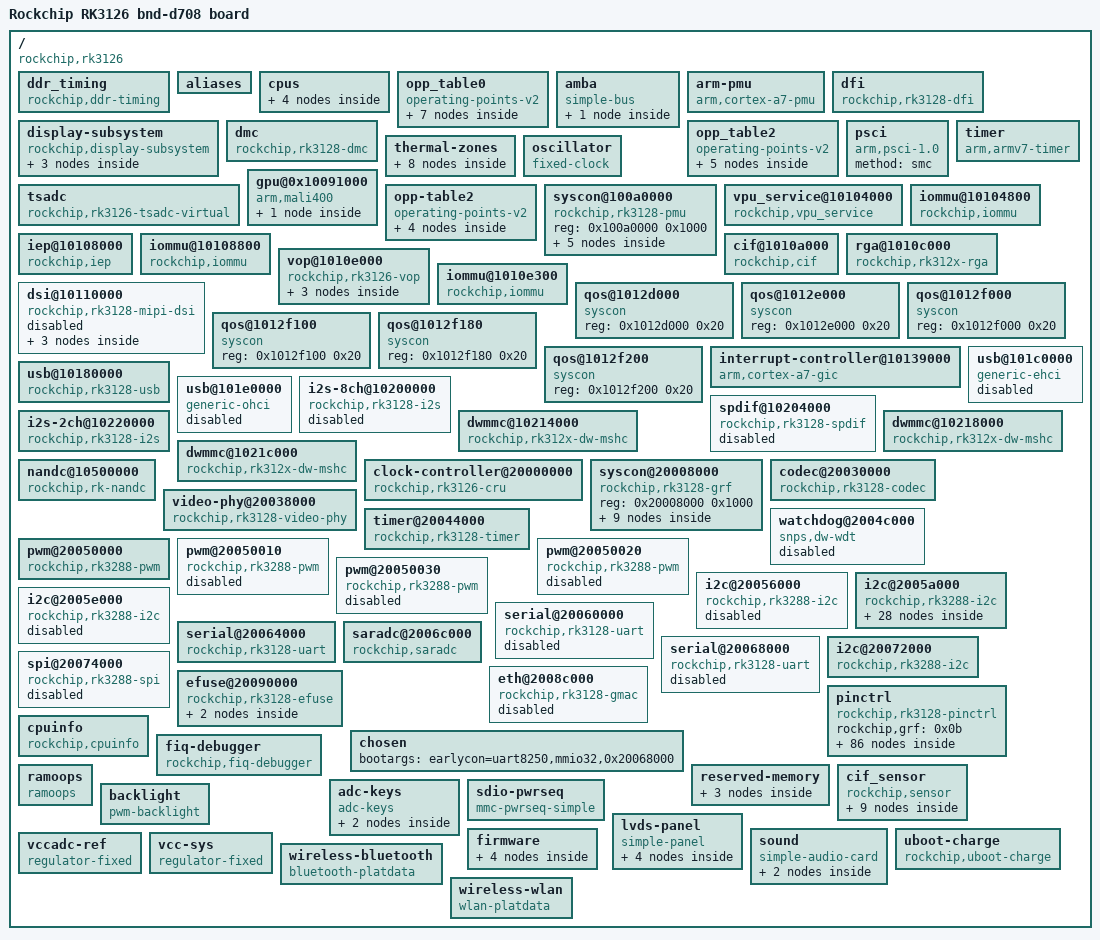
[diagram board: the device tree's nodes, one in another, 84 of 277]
/dts-v1/;

/ {
	interrupt-parent = <0x01>;
	#address-cells = <0x01>;
	#size-cells = <0x01>;
	compatible = "rockchip,rk3126";
	model = "Rockchip RK3126 bnd-d708 board";

	ddr_timing {
		compatible = "rockchip,ddr-timing";
		ddr3_speed_bin = <0x15>;
		pd_idle = <0x40>;
		sr_idle = <0x01>;
		auto_pd_dis_freq = <0x64>;
		auto_sr_dis_freq = <0x64>;
		ddr3_dll_dis_freq = <0x64>;
		lpddr2_dll_dis_freq = <0x12c>;
		phy_dll_dis_freq = <0x64>;
		ddr3_odt_dis_freq = <0x64>;
		phy_ddr3_odt_disb_freq = <0x64>;
		ddr3_drv = <0x02>;
		ddr3_odt = <0x40>;
		phy_ddr3_clk_drv = <0x0d>;
		phy_ddr3_cmd_drv = <0x0d>;
		phy_ddr3_dqs_drv = <0x0d>;
		phy_ddr3_odt = <0x04>;
		lpddr2_drv = <0x01>;
		phy_lpddr2_clk_drv = <0x0b>;
		phy_lpddr2_cmd_drv = <0x0b>;
		phy_lpddr2_dqs_drv = <0x0b>;
		linux,phandle = <0x13>;
		phandle = <0x13>;
	};

	aliases {
		serial0 = "/serial@20060000";
		serial1 = "/serial@20064000";
		serial2 = "/serial@20068000";
		i2c0 = "/i2c@20072000";
		i2c1 = "/i2c@20056000";
		i2c2 = "/i2c@2005a000";
		i2c3 = "/i2c@2005e000";
	};

	cpus {
		#address-cells = <0x01>;
		#size-cells = <0x00>;

		cpu@f00 {
			device_type = "cpu";
			compatible = "arm,cortex-a7";
			reg = <0xf00>;
			operating-points-v2 = <0x02>;
			clocks = <0x03 0x05>;
			#cooling-cells = <0x02>;
			dynamic-power-coefficient = <0x78>;
			cpu-supply = <0x04>;
			linux,phandle = <0x06>;
			phandle = <0x06>;
		};

		cpu@f01 {
			device_type = "cpu";
			compatible = "arm,cortex-a7";
			reg = <0xf01>;
			operating-points-v2 = <0x02>;
			linux,phandle = <0x07>;
			phandle = <0x07>;
		};

		cpu@f02 {
			device_type = "cpu";
			compatible = "arm,cortex-a7";
			reg = <0xf02>;
			operating-points-v2 = <0x02>;
			linux,phandle = <0x08>;
			phandle = <0x08>;
		};

		cpu@f03 {
			device_type = "cpu";
			compatible = "arm,cortex-a7";
			reg = <0xf03>;
			operating-points-v2 = <0x02>;
			linux,phandle = <0x09>;
			phandle = <0x09>;
		};
	};

	opp_table0 {
		compatible = "operating-points-v2";
		opp-shared;
		rockchip,leakage-scaling-sel = <0x01 0x0d 0x12 0x0e 0xfe 0x00>;
		clocks = <0x03 0x01>;
		rockchip,leakage-voltage-sel = <0x01 0x0d 0x00 0x0e 0x12 0x01 0x12 0xfe 0x02>;
		nvmem-cells = <0x05>;
		nvmem-cell-names = "cpu_leakage";
		linux,phandle = <0x02>;
		phandle = <0x02>;

		opp-216000000 {
			opp-hz = <0x00 0xcdfe600>;
			opp-microvolt = <0xf4240>;
			opp-microvolt-L0 = <0xf4240>;
			opp-microvolt-L1 = <0xf4240>;
			opp-microvolt-L2 = <0xf4240>;
			clock-latency-ns = <0x9c40>;
		};

		opp-408000000 {
			opp-hz = <0x00 0x18519600>;
			opp-microvolt = <0xf4240>;
			opp-microvolt-L0 = <0xf4240>;
			opp-microvolt-L1 = <0xf4240>;
			opp-microvolt-L2 = <0xf4240>;
			clock-latency-ns = <0x9c40>;
		};

		opp-600000000 {
			opp-hz = <0x00 0x23c34600>;
			opp-microvolt = <0x118c30>;
			opp-microvolt-L0 = <0x118c30>;
			opp-microvolt-L1 = <0x10c8e0>;
			opp-microvolt-L2 = <0x100590>;
			clock-latency-ns = <0x9c40>;
		};

		opp-696000000 {
			opp-hz = <0x00 0x297c1e00>;
			opp-microvolt = <0x118c30>;
			opp-microvolt-L0 = <0x118c30>;
			opp-microvolt-L1 = <0x10c8e0>;
			opp-microvolt-L2 = <0x100590>;
			clock-latency-ns = <0x9c40>;
		};

		opp-816000000 {
			opp-hz = <0x00 0x30a32c00>;
			opp-microvolt = <0x124f80>;
			opp-microvolt-L0 = <0x124f80>;
			opp-microvolt-L1 = <0x118c30>;
			opp-microvolt-L2 = <0x10c8e0>;
			clock-latency-ns = <0x9c40>;
			opp-suspend;
		};

		opp-1008000000 {
			opp-hz = <0x00 0x3c14dc00>;
			opp-microvolt = <0x1437c8>;
			opp-microvolt-L0 = <0x1437c8>;
			opp-microvolt-L1 = <0x137478>;
			opp-microvolt-L2 = <0x12b128>;
			clock-latency-ns = <0x9c40>;
		};

		opp-1200000000 {
			opp-hz = <0x00 0x47868c00>;
			opp-microvolt = <0x15be68>;
			opp-microvolt-L0 = <0x15be68>;
			opp-microvolt-L1 = <0x15be68>;
			opp-microvolt-L2 = <0x14fb18>;
			clock-latency-ns = <0x9c40>;
		};
	};

	amba {
		compatible = "simple-bus";
		#address-cells = <0x01>;
		#size-cells = <0x01>;
		ranges;

		pdma@20078000 {
			compatible = "arm,pl330", "arm,primecell";
			reg = <0x20078000 0x4000>;
			interrupts = <0x00 0x00 0x04 0x00 0x01 0x04>;
			#dma-cells = <0x01>;
			arm,pl330-broken-no-flushp;
			peripherals-req-type-burst;
			clocks = <0x03 0xc2>;
			clock-names = "apb_pclk";
			linux,phandle = <0x29>;
			phandle = <0x29>;
		};
	};

	arm-pmu {
		compatible = "arm,cortex-a7-pmu";
		interrupts = <0x00 0x4c 0x04 0x00 0x4d 0x04 0x00 0x4e 0x04 0x00 0x4f 0x04>;
		interrupt-affinity = <0x06 0x07 0x08 0x09>;
	};

	dfi {
		compatible = "rockchip,rk3128-dfi";
		rockchip,pmu = <0x0a>;
		rockchip,grf = <0x0b>;
		status = "okay";
		linux,phandle = <0x11>;
		phandle = <0x11>;
	};

	display-subsystem {
		compatible = "rockchip,display-subsystem";
		ports = <0x0c>;
		status = "okay";
		memory-region = <0x0d>;
		logo-memory-region = <0x0e>;

		route {

			route-dsi {
				status = "disabled";
				logo,uboot = "logo.bmp";
				logo,kernel = "logo_kernel.bmp";
				logo,mode = "center";
				charge_logo,mode = "center";
				connect = <0x0f>;
			};

			route-lvds {
				status = "okay";
				logo,uboot = "logo.bmp";
				logo,kernel = "logo_kernel.bmp";
				logo,mode = "center";
				charge_logo,mode = "center";
				connect = <0x10>;
			};
		};
	};

	dmc {
		compatible = "rockchip,rk3128-dmc";
		devfreq-events = <0x11>;
		clocks = <0x03 0x90>;
		clock-names = "dmc_clk";
		upthreshold = <0x37>;
		downdifferential = <0x0a>;
		operating-points-v2 = <0x12>;
		vop-dclk-mode = <0x01>;
		min-cpu-freq = <0x927c0>;
		rockchip,ddr_timing = <0x13>;
		system-status-freq = <0x01 0x57e40>;
		auto-min-freq = <0x493e0>;
		auto-freq-en = <0x00>;
		status = "okay";
		center-supply = <0x14>;
	};

	opp_table2 {
		compatible = "operating-points-v2";
		linux,phandle = <0x12>;
		phandle = <0x12>;

		opp-200000000 {
			opp-hz = <0x00 0xbebc200>;
			opp-microvolt = <0x1312d0>;
		};

		opp-300000000 {
			opp-hz = <0x00 0x11e1a300>;
			opp-microvolt = <0x1312d0>;
		};

		opp-360000000 {
			opp-hz = <0x00 0x15752a00>;
			opp-microvolt = <0x1312d0>;
		};

		opp-396000000 {
			opp-hz = <0x00 0x179a7b00>;
			opp-microvolt = <0x1312d0>;
		};

		opp-456000000 {
			opp-hz = <0x00 0x1b2e0200>;
			opp-microvolt = <0x1312d0>;
		};
	};

	psci {
		compatible = "arm,psci-1.0";
		method = "smc";
	};

	timer {
		compatible = "arm,armv7-timer";
		interrupts = <0x01 0x0d 0xf04 0x01 0x0e 0xf04>;
		clock-frequency = <0x16e3600>;
	};

	thermal-zones {

		soc-thermal {
			polling-delay-passive = <0x3e8>;
			polling-delay = <0x7d0>;
			sustainable-power = <0xc8>;
			thermal-sensors = <0x15 0x00>;

			trips {

				trip-point0 {
					temperature = <0x13880>;
					hysteresis = <0x7d0>;
					type = "passive";
				};

				trip-point1 {
					temperature = <0x15f90>;
					hysteresis = <0x7d0>;
					type = "passive";
					linux,phandle = <0x16>;
					phandle = <0x16>;
				};

				soc-crit {
					temperature = <0x186a0>;
					hysteresis = <0x7d0>;
					type = "critical";
				};
			};

			cooling-maps {

				map0 {
					trip = <0x16>;
					cooling-device = <0x06 0xffffffff 0xffffffff>;
					contribution = <0x400>;
				};

				map1 {
					trip = <0x16>;
					cooling-device = <0x17 0xffffffff 0xffffffff>;
					contribution = <0x400>;
				};
			};
		};
	};

	tsadc {
		compatible = "rockchip,rk3126-tsadc-virtual";
		nvmem-cells = <0x05>;
		nvmem-cell-names = "cpu_leakage";
		#thermal-sensor-cells = <0x01>;
		status = "okay";
		linux,phandle = <0x15>;
		phandle = <0x15>;
	};

	oscillator {
		compatible = "fixed-clock";
		clock-frequency = <0x16e3600>;
		clock-output-names = "xin24m";
		#clock-cells = <0x00>;
		linux,phandle = <0x36>;
		phandle = <0x36>;
	};

	gpu@0x10091000 {
		compatible = "arm,mali400";
		reg = <0x10091000 0x200 0x10090000 0x100 0x10093000 0x100 0x10098000 0x1100 0x10094000 0x100 0x1009a000 0x1100 0x10095000 0x100>;
		reg-names = "Mali_L2", "Mali_GP", "Mali_GP_MMU", "Mali_PP0", "Mali_PP0_MMU", "Mali_PP1", "Mali_PP1_MMU";
		interrupts = <0x00 0x03 0x04 0x00 0x04 0x04 0x00 0x05 0x04 0x00 0x04 0x04 0x00 0x05 0x04 0x00 0x04 0x04>;
		interrupt-names = "Mali_GP_IRQ", "Mali_GP_MMU_IRQ", "Mali_PP0_IRQ", "Mali_PP0_MMU_IRQ", "Mali_PP1_IRQ", "Mali_PP1_MMU_IRQ";
		clocks = <0x03 0xd5>;
		#cooling-cells = <0x02>;
		clock-names = "clk_mali";
		power-domains = <0x18 0x03>;
		operating-points-v2 = <0x19>;
		status = "okay";
		mali-supply = <0x14>;
		linux,phandle = <0x17>;
		phandle = <0x17>;

		power_model {
			compatible = "arm,mali-simple-power-model";
			voltage = <0x384>;
			frequency = <0x1f4>;
			static-power = <0x12c>;
			dynamic-power = <0x18c>;
			ts = <0x7d00 0x125c 0xffffffb0 0x02>;
			thermal-zone = "soc-thermal";
		};
	};

	opp-table2 {
		compatible = "operating-points-v2";
		linux,phandle = <0x19>;
		phandle = <0x19>;

		opp-200000000 {
			opp-hz = <0x00 0xbebc200>;
			opp-microvolt = <0xee098>;
		};

		opp-300000000 {
			opp-hz = <0x00 0x11e1a300>;
			opp-microvolt = <0x100590>;
		};

		opp-400000000 {
			opp-hz = <0x00 0x17d78400>;
			opp-microvolt = <0x118c30>;
		};

		opp-480000000 {
			opp-hz = <0x00 0x1c9c3800>;
			opp-microvolt = <0x1312d0>;
		};
	};

	syscon@100a0000 {
		compatible = "rockchip,rk3128-pmu", "syscon", "simple-mfd";
		reg = <0x100a0000 0x1000>;
		#address-cells = <0x01>;
		#size-cells = <0x01>;
		linux,phandle = <0x0a>;
		phandle = <0x0a>;

		power-controller {
			compatible = "rockchip,rk3128-power-controller";
			#power-domain-cells = <0x01>;
			#address-cells = <0x01>;
			#size-cells = <0x00>;
			status = "okay";
			linux,phandle = <0x18>;
			phandle = <0x18>;

			pd_vio@1 {
				reg = <0x01>;
				clocks = <0x03 0xcd 0x03 0xcc 0x03 0xc7 0x03 0xc6 0x03 0xc0 0x03 0xc1 0x03 0xbe 0x03 0xbf 0x03 0x1d3 0x03 0x1d2 0x03 0x1d1 0x03 0x1cf 0x03 0x1d4 0x03 0x1d6 0x03 0x1d5 0x03 0x145 0x03 0x172 0x03 0x7a>;
				pm_qos = <0x1a 0x1b 0x1c 0x1d>;
			};

			pd_video@2 {
				reg = <0x02>;
				clocks = <0x03 0xc4 0x03 0xc5 0x03 0x1cd 0x03 0x1ce 0x03 0x86>;
				pm_qos = <0x1e>;
			};

			pd_gpu@3 {
				reg = <0x03>;
				clocks = <0x03 0xd5>;
				pm_qos = <0x1f>;
			};
		};

		reboot-mode {
			compatible = "syscon-reboot-mode";
			offset = <0x38>;
			mode-bootloader = <0x5242c301>;
			mode-charge = <0x5242c30b>;
			mode-fastboot = <0x5242c309>;
			mode-loader = <0x5242c301>;
			mode-normal = <0x5242c300>;
			mode-recovery = <0x5242c303>;
			mode-ums = <0x5242c30c>;
		};
	};

	vpu_service@10104000 {
		compatible = "rockchip,vpu_service";
		rockchip,grf = <0x0b>;
		iommus = <0x20>;
		iommu_enabled = <0x01>;
		reg = <0x10104000 0x800>;
		interrupts = <0x00 0x06 0x04 0x00 0x07 0x04>;
		interrupt-names = "irq_enc", "irq_dec";
		clocks = <0x03 0xc5 0x03 0x1ce>;
		clock-names = "aclk_vcodec", "hclk_vcodec";
		resets = <0x03 0x71 0x03 0x70>;
		reset-names = "video_h", "video_a";
		power-domains = <0x18 0x02>;
		dev_mode = <0x00>;
		allocator = <0x01>;
		status = "okay";
	};

	iommu@10104800 {
		compatible = "rockchip,iommu";
		reg = <0x10104800 0x40>;
		interrupts = <0x00 0x43 0x04>;
		interrupt-names = "vpu_mmu";
		clocks = <0x03 0xc5 0x03 0x1ce>;
		clock-names = "aclk", "hclk";
		power-domains = <0x18 0x02>;
		#iommu-cells = <0x00>;
		linux,phandle = <0x20>;
		phandle = <0x20>;
	};

	iep@10108000 {
		compatible = "rockchip,iep";
		iommu_enabled = <0x01>;
		iommus = <0x21>;
		reg = <0x10108000 0x800>;
		interrupts = <0x00 0x30 0x04 0x00>;
		clocks = <0x03 0xc7 0x03 0x1d4>;
		clock-names = "aclk_iep", "hclk_iep";
		power-domains = <0x18 0x01>;
		allocator = <0x01>;
		version = <0x01>;
		status = "okay";
	};

	iommu@10108800 {
		compatible = "rockchip,iommu";
		reg = <0x10108800 0x40>;
		interrupts = <0x00 0x30 0x04 0x00>;
		interrupt-names = "iep_mmu";
		clocks = <0x03 0xc7 0x03 0x1d4>;
		clock-names = "aclk", "hclk";
		power-domains = <0x18 0x01>;
		#iommu-cells = <0x00>;
		status = "okay";
		linux,phandle = <0x21>;
		phandle = <0x21>;
	};

	cif@1010a000 {
		compatible = "rockchip,cif";
		reg = <0x1010a000 0x200>;
		interrupts = <0x00 0x08 0x04>;
		clocks = <0x03 0xc6 0x03 0x1d6 0x03 0x96 0x03 0x98>;
		clock-names = "aclk_cif0", "hclk_cif0", "cif0_in", "cif0_out";
		resets = <0x03 0x6e>;
		reset-names = "rst_cif";
		power-domains = <0x18 0x01>;
		status = "okay";
	};

	rga@1010c000 {
		compatible = "rockchip,rk312x-rga";
		reg = <0x1010c000 0x1000>;
		interrupts = <0x00 0x2c 0x04>;
		clocks = <0x03 0xcd 0x03 0x1d3 0x03 0x87>;
		clock-names = "aclk_rga", "hclk_rga", "sclk_rga";
		power-domains = <0x18 0x01>;
		dma-coherent;
		status = "okay";
	};

	vop@1010e000 {
		compatible = "rockchip,rk3126-vop";
		reg = <0x1010e000 0x100 0x1010ec00 0x400>;
		reg-names = "regs", "gamma_lut";
		interrupts = <0x00 0x09 0x04>;
		clocks = <0x03 0xcc 0x03 0xbe 0x03 0x1cf>;
		clock-names = "aclk_vop", "dclk_vop", "hclk_vop";
		resets = <0x03 0x64 0x03 0x66 0x03 0x65>;
		reset-names = "axi", "ahb", "dclk";
		power-domains = <0x18 0x01>;
		status = "okay";

		port {
			#address-cells = <0x01>;
			#size-cells = <0x00>;
			linux,phandle = <0x0c>;
			phandle = <0x0c>;

			endpoint@0 {
				reg = <0x00>;
				remote-endpoint = <0x23>;
				linux,phandle = <0x0f>;
				phandle = <0x0f>;
			};

			endpoint@1 {
				reg = <0x01>;
				remote-endpoint = <0x24>;
				linux,phandle = <0x10>;
				phandle = <0x10>;
			};
		};
	};

	iommu@1010e300 {
		compatible = "rockchip,iommu";
		reg = <0x1010e300 0x100>;
		interrupts = <0x00 0x09 0x04>;
		interrupt-names = "vop_mmu";
		clocks = <0x03 0xcc 0x03 0x1cf>;
		clock-names = "aclk", "hclk";
		power-domains = <0x18 0x01>;
		#iommu-cells = <0x00>;
		status = "okay";
		linux,phandle = <0x22>;
		phandle = <0x22>;
	};

	dsi@10110000 {
		compatible = "rockchip,rk3128-mipi-dsi";
		reg = <0x10110000 0x4000>;
		interrupts = <0x00 0x21 0x04>;
		clocks = <0x03 0x145 0x03 0x1d5 0x25>;
		clock-names = "pclk", "h2p", "hs_clk";
		resets = <0x03 0x89>;
		reset-names = "apb";
		phys = <0x25>;
		phy-names = "mipi_dphy";
		power-domains = <0x18 0x01>;
		rockchip,grf = <0x0b>;
		#address-cells = <0x01>;
		#size-cells = <0x00>;
		status = "disabled";

		ports {

			port {

				endpoint {
					remote-endpoint = <0x0f>;
					linux,phandle = <0x23>;
					phandle = <0x23>;
				};
			};
		};
	};

	qos@1012d000 {
		compatible = "syscon";
		reg = <0x1012d000 0x20>;
		linux,phandle = <0x1f>;
		phandle = <0x1f>;
	};

	qos@1012e000 {
		compatible = "syscon";
		reg = <0x1012e000 0x20>;
		linux,phandle = <0x1e>;
		phandle = <0x1e>;
	};

	qos@1012f000 {
		compatible = "syscon";
		reg = <0x1012f000 0x20>;
		linux,phandle = <0x1a>;
		phandle = <0x1a>;
	};

	qos@1012f100 {
		compatible = "syscon";
		reg = <0x1012f100 0x20>;
		linux,phandle = <0x1b>;
		phandle = <0x1b>;
	};

	qos@1012f180 {
		compatible = "syscon";
		reg = <0x1012f180 0x20>;
		linux,phandle = <0x1c>;
		phandle = <0x1c>;
	};

	qos@1012f200 {
		compatible = "syscon";
		reg = <0x1012f200 0x20>;
		linux,phandle = <0x1d>;
		phandle = <0x1d>;
	};

	interrupt-controller@10139000 {
		compatible = "arm,cortex-a7-gic";
		interrupt-controller;
		#interrupt-cells = <0x03>;
		#address-cells = <0x00>;
		reg = <0x10139000 0x1000 0x1013a000 0x1000 0x1013c000 0x2000 0x1013e000 0x2000>;
		interrupts = <0x01 0x09 0xf04>;
		linux,phandle = <0x01>;
		phandle = <0x01>;
	};

	usb@10180000 {
		compatible = "rockchip,rk3128-usb", "rockchip,rk3066-usb", "snps,dwc2";
		reg = <0x10180000 0x40000>;
		interrupts = <0x00 0x0a 0x04>;
		clocks = <0x03 0x1da>;
		clock-names = "otg";
		dr_mode = "otg";
		g-np-tx-fifo-size = <0x10>;
		g-rx-fifo-size = <0x113>;
		g-tx-fifo-size = <0x100 0x80 0x80 0x40 0x40 0x20>;
		g-use-dma;
		phys = <0x26>;
		phy-names = "usb2-phy";
		status = "okay";
	};

	usb@101c0000 {
		compatible = "generic-ehci";
		reg = <0x101c0000 0x20000>;
		interrupts = <0x00 0x0b 0x04>;
		clocks = <0x03 0x1d9 0x27>;
		clock-names = "usbhost", "utmi";
		phys = <0x28>;
		phy-names = "usb";
		status = "disabled";
	};

	usb@101e0000 {
		compatible = "generic-ohci";
		reg = <0x101e0000 0x20000>;
		interrupts = <0x00 0x20 0x04>;
		clocks = <0x03 0x1d9 0x27>;
		clock-names = "usbhost", "utmi";
		phys = <0x28>;
		phy-names = "usb";
		status = "disabled";
	};

	i2s-8ch@10200000 {
		compatible = "rockchip,rk3128-i2s", "rockchip,rk3066-i2s";
		reg = <0x10200000 0x1000>;
		clocks = <0x03 0x50 0x03 0x1bb>;
		clock-names = "i2s_clk", "i2s_hclk";
		interrupts = <0x00 0x44 0x04>;
		dmas = <0x29 0x0e 0x29 0x0f>;
		dma-names = "tx", "rx";
		status = "disabled";
	};

	spdif@10204000 {
		compatible = "rockchip,rk3128-spdif";
		reg = <0x10204000 0x1000>;
		interrupts = <0x00 0x37 0x04>;
		clocks = <0x03 0x53 0x03 0x1b8>;
		clock-names = "mclk", "hclk";
		dmas = <0x29 0x0d>;
		dma-names = "tx";
		pinctrl-names = "default";
		pinctrl-0 = <0x2a>;
		status = "disabled";
	};

	i2s-2ch@10220000 {
		compatible = "rockchip,rk3128-i2s", "rockchip,rk3066-i2s";
		reg = <0x10220000 0x1000>;
		clocks = <0x03 0x51 0x03 0x1bc>;
		clock-names = "i2s_clk", "i2s_hclk";
		interrupts = <0x00 0x13 0x04>;
		dmas = <0x29 0x00 0x29 0x01>;
		dma-names = "tx", "rx";
		status = "okay";
		#sound-dai-cells = <0x00>;
		linux,phandle = <0x5b>;
		phandle = <0x5b>;
	};

	dwmmc@10214000 {
		compatible = "rockchip,rk312x-dw-mshc", "rockchip,rk3288-dw-mshc";
		reg = <0x10214000 0x4000>;
		interrupts = <0x00 0x0e 0x04>;
		#address-cells = <0x01>;
		#size-cells = <0x00>;
		pinctrl-names = "default";
		pinctrl-0 = <0x2b 0x2c 0x2d>;
		clock-freq-min-max = <0x61a80 0x2faf080>;
		clocks = <0x03 0x1c8 0x03 0x44>;
		clock-names = "biu", "ciu";
		dmas = <0x29 0x0a>;
		dma-names = "rx-tx";
		num-slots = <0x01>;
		fifo-depth = <0x100>;
		bus-width = <0x04>;
		status = "okay";
		cap-mmc-highspeed;
		supports-sd;
		card-detect-delay = <0x320>;
		ignore-pm-notify;
		keep-power-in-suspend;
		cd-gpios = <0x2e 0x03 0x01>;
	};

	dwmmc@10218000 {
		compatible = "rockchip,rk312x-dw-mshc", "rockchip,rk3288-dw-mshc";
		reg = <0x10218000 0x4000>;
		interrupts = <0x00 0x0f 0x04>;
		#address-cells = <0x01>;
		#size-cells = <0x00>;
		pinctrl-names = "default";
		pinctrl-0 = <0x2f 0x30 0x31 0x32>;
		clock-freq-min-max = <0x61a80 0x2faf080>;
		clocks = <0x03 0x1c9 0x03 0x45>;
		clock-names = "biu", "ciu";
		dmas = <0x29 0x0b>;
		dma-names = "rx-tx";
		num-slots = <0x01>;
		fifo-depth = <0x100>;
		bus-width = <0x04>;
		status = "okay";
		max-frequency = <0x2faf080>;
		cap-sd-highspeed;
		supports-sdio;
		ignore-pm-notify;
		keep-power-in-suspend;
		non-removable;
		mmc-pwrseq = <0x33>;
	};

	dwmmc@1021c000 {
		compatible = "rockchip,rk312x-dw-mshc", "rockchip,rk3288-dw-mshc";
		reg = <0x1021c000 0x4000>;
		interrupts = <0x00 0x10 0x04>;
		#address-cells = <0x01>;
		#size-cells = <0x00>;
		clock-freq-min-max = <0x61a80 0x2faf080>;
		clocks = <0x03 0x1cb 0x03 0x47>;
		clock-names = "biu", "ciu";
		dmas = <0x29 0x0c>;
		dma-names = "rx-tx";
		num-slots = <0x01>;
		fifo-depth = <0x100>;
		bus-width = <0x08>;
		status = "okay";
		cap-mmc-highspeed;
		supports-emmc;
		disable-wp;
		non-removable;
	};

	nandc@10500000 {
		compatible = "rockchip,rk-nandc";
		reg = <0x10500000 0x4000>;
		interrupts = <0x00 0x12 0x04>;
		nandc_id = <0x00>;
		clocks = <0x03 0x43 0x03 0x1c5>;
		clock-names = "clk_nandc", "hclk_nandc";
		status = "okay";
	};

	clock-controller@20000000 {
		compatible = "rockchip,rk3126-cru";
		reg = <0x20000000 0x1000>;
		rockchip,grf = <0x0b>;
		#clock-cells = <0x01>;
		#reset-cells = <0x01>;
		assigned-clocks = <0x03 0x04 0x03 0x03 0x03 0xc3 0x03 0x1cc 0x03 0x162 0x03 0xd2 0x03 0x1de 0x03 0x16b>;
		assigned-clock-rates = <0x2367b880 0x17d78400 0x11e1a300 0x8f0d180 0x47868c0 0x11e1a300 0x8f0d180 0x47868c0>;
		linux,phandle = <0x03>;
		phandle = <0x03>;
	};

	syscon@20008000 {
		compatible = "rockchip,rk3128-grf", "syscon", "simple-mfd";
		reg = <0x20008000 0x1000>;
		#address-cells = <0x01>;
		#size-cells = <0x01>;
		linux,phandle = <0x0b>;
		phandle = <0x0b>;

		usb2-phy@17c {
			compatible = "rockchip,rk3128-usb2phy";
			reg = <0x17c 0x0c>;
			clocks = <0x03 0x8e>;
			clock-names = "phyclk";
			#clock-cells = <0x00>;
			clock-output-names = "usb480m_phy";
			assigned-clocks = <0x03 0x9a>;
			assigned-clock-parents = <0x27>;
			status = "okay";
			linux,phandle = <0x27>;
			phandle = <0x27>;

			otg-port {
				#phy-cells = <0x00>;
				interrupts = <0x00 0x23 0x04 0x00 0x33 0x04 0x00 0x34 0x04>;
				interrupt-names = "otg-bvalid", "otg-id", "linestate";
				status = "okay";
				linux,phandle = <0x26>;
				phandle = <0x26>;
			};

			host-port {
				#phy-cells = <0x00>;
				interrupts = <0x00 0x35 0x04>;
				interrupt-names = "linestate";
				status = "okay";
				linux,phandle = <0x28>;
				phandle = <0x28>;
			};
		};
		lvds {
			compatible = "rockchip,rk3126-lvds";
			phys = <0x25>;
			phy-names = "phy";
			status = "okay";
			pinctrl-names = "lcdc";
			pinctrl-0 = <0x34>;

			ports {
				#address-cells = <0x01>;
				#size-cells = <0x00>;

				port@0 {
					reg = <0x00>;

					endpoint {
						remote-endpoint = <0x10>;
						linux,phandle = <0x24>;
						phandle = <0x24>;
					};
				};

				port@1 {
					reg = <0x01>;
					#address-cells = <0x01>;
					#size-cells = <0x00>;

					endpoint@0 {
						reg = <0x00>;
						remote-endpoint = <0x35>;
						linux,phandle = <0x59>;
						phandle = <0x59>;
					};
				};
			};
		};
	};

	codec@20030000 {
		compatible = "rockchip,rk3128-codec";
		reg = <0x20030000 0x4000>;
		interrupts = <0x00 0x60 0x04>;
		boot_depop = <0x01>;
		pa_enable_time = <0x3e8>;
		rockchip,grf = <0x0b>;
		clocks = <0x03 0x148 0x03 0x51>;
		clock-names = "g_pclk_acodec", "i2s_clk";
		status = "okay";
		#sound-dai-cells = <0x00>;
		spk-ctl-gpios = <0x2e 0x0b 0x00>;
		spk-mute-delay = <0xc8>;
		hp-mute-delay = <0x64>;
		is_rk3128 = <0x00>;
		spk_volume = <0x1c>;
		hp_volume = <0x19>;
		capture_volume = <0x18>;
		gpio_debug = <0x01>;
		codec_hp_det = <0x00>;
		linux,phandle = <0x5c>;
		phandle = <0x5c>;
	};

	video-phy@20038000 {
		compatible = "rockchip,rk3128-video-phy";
		reg = <0x20038000 0x4000 0x10110000 0x4000>;
		clocks = <0x3 0x94 0x3 0x172 0x3 0x145 0x3 0x1d5>;
		clock-names = "ref", "pclk_phy", "pclk_host", "h2p";
		clock-output-names = "mipi_dphy_pll";
		#clock-cells = <0x0>;
		resets = <0x3 0x24>;
		reset-names = "rst";
		power-domains = <0x18 0x1>;
		rockchip,grf = <0xb>;
		#phy-cells = <0x0>;
		status = "okay";
		linux,phandle = <0x25>;
		phandle = <0x25>;
	};



	timer@20044000 {
		compatible = "rockchip,rk3128-timer", "rockchip,rk3288-timer";
		reg = <0x20044000 0x20>;
		interrupts = <0x00 0x1c 0x04>;
		clocks = <0x36 0x03 0x161>;
		clock-names = "timer", "pclk";
	};

	watchdog@2004c000 {
		compatible = "snps,dw-wdt";
		reg = <0x2004c000 0x100>;
		clocks = <0x03 0x13f>;
		interrupts = <0x00 0x22 0x04 0x00>;
		status = "disabled";
	};

	pwm@20050000 {
		compatible = "rockchip,rk3288-pwm";
		reg = <0x20050000 0x10>;
		#pwm-cells = <0x03>;
		pinctrl-names = "active";
		pinctrl-0 = <0x37>;
		clocks = <0x03 0x15e>;
		clock-names = "pwm";
		status = "okay";
		linux,phandle = <0x57>;
		phandle = <0x57>;
	};

	pwm@20050010 {
		compatible = "rockchip,rk3288-pwm";
		reg = <0x20050010 0x10>;
		#pwm-cells = <0x03>;
		pinctrl-names = "default";
		pinctrl-0 = <0x38>;
		clocks = <0x03 0x15e>;
		clock-names = "pwm";
		status = "disabled";
	};

	pwm@20050020 {
		compatible = "rockchip,rk3288-pwm";
		reg = <0x20050020 0x10>;
		#pwm-cells = <0x03>;
		pinctrl-names = "default";
		pinctrl-0 = <0x39>;
		clocks = <0x03 0x15e>;
		clock-names = "pwm";
		status = "disabled";
	};

	pwm@20050030 {
		compatible = "rockchip,rk3288-pwm";
		reg = <0x20050030 0x10>;
		#pwm-cells = <0x03>;
		pinctrl-names = "default";
		pinctrl-0 = <0x3a>;
		clocks = <0x03 0x15e>;
		clock-names = "pwm";
		status = "disabled";
	};

	i2c@20056000 {
		compatible = "rockchip,rk3288-i2c";
		reg = <0x20056000 0x1000>;
		interrupts = <0x00 0x19 0x04>;
		#address-cells = <0x01>;
		#size-cells = <0x00>;
		clock-names = "i2c";
		clocks = <0x03 0x14d>;
		pinctrl-names = "default";
		pinctrl-0 = <0x3b>;
		status = "disabled";
	};

	i2c@2005a000 {
		compatible = "rockchip,rk3288-i2c";
		reg = <0x2005a000 0x1000>;
		interrupts = <0x00 0x1a 0x04>;
		#address-cells = <0x01>;
		#size-cells = <0x00>;
		clock-names = "i2c";
		clocks = <0x03 0x14e>;
		pinctrl-names = "default";
		pinctrl-0 = <0x3c>;
		status = "okay";

		pmic@1a {
			compatible = "rockchip,rk816";
			reg = <0x1a>;
			interrupt-parent = <0x3d>;
			interrupts = <0x02 0x08>;
			pinctrl-names = "default";
			pinctrl-0 = <0x3e>;
			rockchip,system-power-controller;
			wakeup-source;
			gpio-controller;
			#gpio-cells = <0x02>;
			#clock-cells = <0x01>;
			clock-output-names = "xin32k", "rk816-clkout2";
			extcon = <0x27>;
			vcc1-supply = <0x3f>;
			vcc2-supply = <0x3f>;
			vcc3-supply = <0x3f>;
			vcc4-supply = <0x3f>;
			vcc5-supply = <0x40>;
			vcc6-supply = <0x3f>;
			linux,phandle = <0x55>;
			phandle = <0x55>;

			gpio {
				status = "okay";
			};

			pwrkey {
				status = "okay";
			};

			rtc {
				status = "okay";
			};

			battery {
				compatible = "rk816-battery";
				ocv_table = <0xd7a 0xe57 0xe66 0xe7a 0xe93 0xea2 0xeb2 0xec1 0xecd 0xeda 0xee9 0xefc 0xf12 0xf39 0xf67 0xf87 0xfa5 0xfd8 0xffd 0x102b 0x1068>;
				design_capacity = <0x10af>;
				design_qmax = <0x125a>;
				bat_res = <0x64>;
				max_input_current = <0x640>;
				max_chrg_current = <0x578>;
				max_chrg_voltage = <0x1068>;
				sleep_enter_current = <0x12c>;
				sleep_exit_current = <0x12c>;
				sleep_filter_current = <0x64>;
				power_off_thresd = <0xd7a>;
				zero_algorithm_vol = <0xf0a>;
				max_soc_offset = <0x3c>;
				monitor_sec = <0x05>;
				virtual_power = <0x00>;
				power_dc2otg = <0x00>;
				dc_det_adc = <0x00>;
			};

			regulators {

				DCDC_REG1 {
					regulator-name = "vdd_arm";
					regulator-min-microvolt = <0xb71b0>;
					regulator-max-microvolt = <0x16e360>;
					regulator-ramp-delay = <0x1771>;
					regulator-initial-mode = <0x01>;
					regulator-always-on;
					regulator-boot-on;
					linux,phandle = <0x04>;
					phandle = <0x04>;

					regulator-state-mem {
						regulator-off-in-suspend;
						regulator-suspend-microvolt = <0xdbba0>;
					};
				};

				DCDC_REG2 {
					regulator-name = "vdd_logic";
					regulator-min-microvolt = <0xb71b0>;
					regulator-max-microvolt = <0x16e360>;
					regulator-ramp-delay = <0x1771>;
					regulator-initial-mode = <0x01>;
					regulator-always-on;
					regulator-boot-on;
					linux,phandle = <0x14>;
					phandle = <0x14>;

					regulator-state-mem {
						regulator-on-in-suspend;
						regulator-suspend-microvolt = <0xf4240>;
					};
				};

				DCDC_REG3 {
					regulator-name = "vcc_ddr";
					regulator-always-on;
					regulator-boot-on;
					regulator-initial-mode = <0x01>;
				};

				DCDC_REG4 {
					regulator-name = "vcc_io";
					regulator-min-microvolt = <0x325aa0>;
					regulator-max-microvolt = <0x325aa0>;
					regulator-initial-mode = <0x01>;
					regulator-always-on;
					regulator-boot-on;
					linux,phandle = <0x40>;
					phandle = <0x40>;

					regulator-state-mem {
						regulator-on-in-suspend;
						regulator-suspend-microvolt = <0x2dc6c0>;
					};
				};

				LDO_REG1 {
					regulator-name = "vcc28_cif";
					regulator-min-microvolt = <0x2ab980>;
					regulator-max-microvolt = <0x2ab980>;
					regulator-always-on;
					regulator-boot-on;

					regulator-state-mem {
						regulator-off-in-suspend;
					};
				};

				LDO_REG2 {
					regulator-name = "vcc18_cif";
					regulator-min-microvolt = <0x1b7740>;
					regulator-max-microvolt = <0x1b7740>;
					regulator-always-on;
					regulator-boot-on;

					regulator-state-mem {
						regulator-off-in-suspend;
					};
				};

				LDO_REG3 {
					regulator-name = "vdd_11";
					regulator-min-microvolt = <0x10c8e0>;
					regulator-max-microvolt = <0x10c8e0>;
					regulator-always-on;
					regulator-boot-on;

					regulator-state-mem {
						regulator-on-in-suspend;
						regulator-suspend-microvolt = <0x10c8e0>;
					};
				};

				LDO_REG4 {
					regulator-name = "ldo4";
					regulator-min-microvolt = <0x325aa0>;
					regulator-max-microvolt = <0x325aa0>;
					regulator-always-on;
					regulator-boot-on;

					regulator-state-mem {
						regulator-off-in-suspend;
					};
				};

				LDO_REG5 {
					regulator-name = "ldo5";
					regulator-min-microvolt = <0x325aa0>;
					regulator-max-microvolt = <0x325aa0>;
					regulator-always-on;
					regulator-boot-on;

					regulator-state-mem {
						regulator-on-in-suspend;
						regulator-suspend-microvolt = <0x2dc6c0>;
					};
				};

				LDO_REG6 {
					regulator-name = "ldo6";
					regulator-min-microvolt = <0x325aa0>;
					regulator-max-microvolt = <0x325aa0>;
					regulator-boot-on;
					regulator-always-on;

					regulator-state-mem {
						regulator-off-in-suspend;
						regulator-suspend-microvolt = <0x325aa0>;
					};
				};
			};
		};

		ts@40 {
			compatible = "GSL,GSL3673";
			reg = <0x40>;
			irq_gpio_number = <0x2e 0x0f 0x08>;
			rst_gpio_number = <0x2e 0x0e 0x00>;
			status = "okay";
		};

		sensor@18 {
			compatible = "gs_stk8baxx";
			reg = <0x18>;
			type = <0x02>;
			irq_enable = <0x00>;
			poll_delay_ms = <0x0a>;
			layout = <0x01>;
			status = "okay";
		};

		sensor@19 {
			compatible = "gs_sc7660";
			reg = <0x19>;
			type = <0x02>;
			irq_enable = <0x00>;
			poll_delay_ms = <0x0a>;
			layout = <0x01>;
			status = "okay";
		};
	};

	i2c@2005e000 {
		compatible = "rockchip,rk3288-i2c";
		reg = <0x2005e000 0x1000>;
		interrupts = <0x00 0x1b 0x04>;
		#address-cells = <0x01>;
		#size-cells = <0x00>;
		clock-names = "i2c";
		clocks = <0x03 0x14f>;
		pinctrl-names = "default";
		pinctrl-0 = <0x41>;
		status = "disabled";
	};

	serial@20060000 {
		compatible = "rockchip,rk3128-uart", "snps,dw-apb-uart";
		reg = <0x20060000 0x100>;
		interrupts = <0x00 0x14 0x04>;
		clock-frequency = <0x16e3600>;
		clocks = <0x03 0x4d 0x03 0x155>;
		clock-names = "baudclk", "apb_pclk";
		reg-shift = <0x02>;
		reg-io-width = <0x04>;
		pinctrl-names = "default";
		pinctrl-0 = <0x42 0x43 0x44>;
		status = "disabled";
	};

	serial@20064000 {
		compatible = "rockchip,rk3128-uart", "snps,dw-apb-uart";
		reg = <0x20064000 0x100>;
		interrupts = <0x00 0x15 0x04>;
		clock-frequency = <0x16e3600>;
		clocks = <0x03 0x4e 0x03 0x156>;
		clock-names = "baudclk", "apb_pclk";
		reg-shift = <0x02>;
		reg-io-width = <0x04>;
		pinctrl-names = "default";
		pinctrl-0 = <0x45 0x46>;
		status = "okay";
	};

	serial@20068000 {
		compatible = "rockchip,rk3128-uart", "snps,dw-apb-uart";
		reg = <0x20068000 0x100>;
		interrupts = <0x00 0x16 0x04>;
		clock-frequency = <0x16e3600>;
		clocks = <0x03 0x4f 0x03 0x157>;
		clock-names = "baudclk", "apb_pclk";
		reg-shift = <0x02>;
		reg-io-width = <0x04>;
		pinctrl-names = "default";
		pinctrl-0 = <0x47>;
		status = "disabled";
	};

	saradc@2006c000 {
		compatible = "rockchip,saradc";
		reg = <0x2006c000 0x100>;
		interrupts = <0x00 0x11 0x04>;
		#io-channel-cells = <0x01>;
		clocks = <0x03 0x5b 0x03 0x13e>;
		clock-names = "saradc", "apb_pclk";
		resets = <0x03 0x57>;
		reset-names = "saradc-apb";
		status = "okay";
		vref-supply = <0x48>;
		linux,phandle = <0x54>;
		phandle = <0x54>;
	};

	i2c@20072000 {
		compatible = "rockchip,rk3288-i2c";
		reg = <0x20072000 0x1000>;
		interrupts = <0x00 0x18 0x04>;
		#address-cells = <0x01>;
		#size-cells = <0x00>;
		clock-names = "i2c";
		clocks = <0x03 0x14c>;
		pinctrl-names = "default";
		pinctrl-0 = <0x49>;
		status = "okay";
	};

	spi@20074000 {
		compatible = "rockchip,rk3288-spi";
		reg = <0x20074000 0x1000>;
		interrupts = <0x00 0x17 0x04>;
		pinctrl-names = "default";
		pinctrl-0 = <0x4a 0x4b 0x4c 0x4d 0x4e>;
		clock-names = "spiclk", "apb_pclk";
		dmas = <0x29 0x08 0x29 0x09>;
		dma-names = "tx", "rx";
		#address-cells = <0x01>;
		#size-cells = <0x00>;
		status = "disabled";
	};

	eth@2008c000 {
		compatible = "rockchip,rk3128-gmac";
		reg = <0x2008c000 0x4000>;
		interrupts = <0x00 0x38 0x04 0x00 0x39 0x04>;
		interrupt-names = "macirq", "eth_wake_irq";
		rockchip,grf = <0x0b>;
		clocks = <0x03 0x7e 0x03 0x81 0x03 0x82 0x03 0x80 0x03 0x7f 0x03 0xd4 0x03 0x16f>;
		clock-names = "stmmaceth", "mac_clk_rx", "mac_clk_tx", "clk_mac_ref", "clk_mac_refout", "aclk_mac", "pclk_mac";
		resets = <0x03 0x38>;
		reset-names = "stmmaceth";
		status = "disabled";
	};

	efuse@20090000 {
		compatible = "rockchip,rk3128-efuse";
		reg = <0x20090000 0x20>;
		#address-cells = <0x01>;
		#size-cells = <0x01>;
		clocks = <0x03 0x146>;
		clock-names = "pclk_efuse";

		id@7 {
			reg = <0x07 0x10>;
			linux,phandle = <0x51>;
			phandle = <0x51>;
		};

		cpu_leakage@17 {
			reg = <0x17 0x01>;
			linux,phandle = <0x05>;
			phandle = <0x05>;
		};
	};

	pinctrl {
		compatible = "rockchip,rk3128-pinctrl";
		rockchip,grf = <0x0b>;
		#address-cells = <0x01>;
		#size-cells = <0x01>;
		ranges;

		gpio0@2007c000 {
			compatible = "rockchip,gpio-bank";
			reg = <0x2007c000 0x100>;
			interrupts = <0x00 0x24 0x04>;
			clocks = <0x03 0x140>;
			gpio-controller;
			#gpio-cells = <0x02>;
			interrupt-controller;
			#interrupt-cells = <0x02>;
			linux,phandle = <0x3d>;
			phandle = <0x3d>;
		};

		gpio1@20080000 {
			compatible = "rockchip,gpio-bank";
			reg = <0x20080000 0x100>;
			interrupts = <0x00 0x25 0x04>;
			clocks = <0x03 0x141>;
			gpio-controller;
			#gpio-cells = <0x02>;
			interrupt-controller;
			#interrupt-cells = <0x02>;
			linux,phandle = <0x5d>;
			phandle = <0x5d>;
		};

		gpio2@20084000 {
			compatible = "rockchip,gpio-bank";
			reg = <0x20084000 0x100>;
			interrupts = <0x00 0x26 0x04>;
			clocks = <0x03 0x142>;
			gpio-controller;
			#gpio-cells = <0x02>;
			interrupt-controller;
			#interrupt-cells = <0x02>;
			linux,phandle = <0x2e>;
			phandle = <0x2e>;
		};

		gpio3@20088000 {
			compatible = "rockchip,gpio-bank";
			reg = <0x20088000 0x100>;
			interrupts = <0x00 0x27 0x04>;
			clocks = <0x03 0x143>;
			gpio-controller;
			#gpio-cells = <0x02>;
			interrupt-controller;
			#interrupt-cells = <0x02>;
			linux,phandle = <0x53>;
			phandle = <0x53>;
		};

		pcfg_pull_default {
			bias-pull-pin-default;
			linux,phandle = <0x50>;
			phandle = <0x50>;
		};

		pcfg-pull-none {
			bias-disable;
			linux,phandle = <0x4f>;
			phandle = <0x4f>;
		};

		emmc {

			emmc-clk {
				rockchip,pins = <0x02 0x07 0x02 0x4f>;
			};

			emmc-cmd {
				rockchip,pins = <0x01 0x16 0x02 0x50>;
			};

			emmc-cmd1 {
				rockchip,pins = <0x02 0x04 0x02 0x50>;
			};

			emmc-pwr {
				rockchip,pins = <0x02 0x05 0x02 0x50>;
			};

			emmc-bus1 {
				rockchip,pins = <0x01 0x18 0x02 0x50>;
			};

			emmc-bus4 {
				rockchip,pins = <0x01 0x18 0x02 0x50 0x01 0x19 0x02 0x50 0x01 0x1a 0x02 0x50 0x01 0x1b 0x02 0x50>;
			};

			emmc-bus8 {
				rockchip,pins = <0x01 0x18 0x02 0x50 0x01 0x19 0x02 0x50 0x01 0x1a 0x02 0x50 0x01 0x1b 0x02 0x50 0x01 0x1c 0x02 0x50 0x01 0x1d 0x02 0x50 0x01 0x1e 0x02 0x50 0x01 0x1f 0x02 0x50>;
			};
		};

		i2c0 {

			i2c0-xfer {
				rockchip,pins = <0x00 0x00 0x01 0x4f 0x00 0x01 0x01 0x4f>;
				linux,phandle = <0x49>;
				phandle = <0x49>;
			};
		};

		i2c1 {

			i2c1-xfer {
				rockchip,pins = <0x00 0x02 0x01 0x4f 0x00 0x03 0x01 0x4f>;
				linux,phandle = <0x3b>;
				phandle = <0x3b>;
			};
		};

		i2c2 {

			i2c2-xfer {
				rockchip,pins = <0x02 0x14 0x03 0x4f 0x02 0x15 0x03 0x4f>;
				linux,phandle = <0x3c>;
				phandle = <0x3c>;
			};
		};

		i2c3 {

			i2c3-xfer {
				rockchip,pins = <0x00 0x06 0x01 0x4f 0x00 0x07 0x01 0x4f>;
				linux,phandle = <0x41>;
				phandle = <0x41>;
			};
		};

		uart0 {

			uart0-xfer {
				rockchip,pins = <0x02 0x1a 0x02 0x50 0x02 0x1b 0x02 0x4f>;
				linux,phandle = <0x42>;
				phandle = <0x42>;
			};

			uart0-cts {
				rockchip,pins = <0x02 0x1d 0x02 0x4f>;
				linux,phandle = <0x43>;
				phandle = <0x43>;
			};

			uart0-rts {
				rockchip,pins = <0x00 0x11 0x02 0x4f>;
				linux,phandle = <0x44>;
				phandle = <0x44>;
			};
		};

		uart1 {

			uart1-xfer {
				rockchip,pins = <0x01 0x09 0x02 0x50 0x01 0x0a 0x02 0x50>;
				linux,phandle = <0x45>;
				phandle = <0x45>;
			};

			uart1-cts {
				rockchip,pins = <0x01 0x08 0x02 0x4f>;
				linux,phandle = <0x46>;
				phandle = <0x46>;
			};

			uart1-rts {
				rockchip,pins = <0x01 0x0b 0x02 0x4f>;
				linux,phandle = <0x5e>;
				phandle = <0x5e>;
			};
		};

		uart2 {

			uart2-xfer {
				rockchip,pins = <0x01 0x12 0x02 0x50 0x01 0x13 0x02 0x4f>;
				linux,phandle = <0x47>;
				phandle = <0x47>;
			};

			uart2-cts {
				rockchip,pins = <0x00 0x19 0x01 0x4f>;
			};

			uart2-rts {
				rockchip,pins = <0x00 0x18 0x01 0x4f>;
			};
		};

		sdmmc {

			sdmmc-clk {
				rockchip,pins = <0x01 0x10 0x01 0x4f>;
				linux,phandle = <0x2b>;
				phandle = <0x2b>;
			};

			sdmmc-cmd {
				rockchip,pins = <0x01 0x0f 0x01 0x50>;
				linux,phandle = <0x2c>;
				phandle = <0x2c>;
			};

			sdmmc-wp {
				rockchip,pins = <0x01 0x07 0x01 0x50>;
			};

			sdmmc-pwren {
				rockchip,pins = <0x01 0x0e 0x01 0x50>;
			};

			sdmmc-bus4 {
				rockchip,pins = <0x01 0x12 0x01 0x50 0x01 0x13 0x01 0x50 0x01 0x14 0x01 0x50 0x01 0x15 0x01 0x50>;
				linux,phandle = <0x2d>;
				phandle = <0x2d>;
			};
		};

		sdio {

			sdio-clk {
				rockchip,pins = <0x01 0x00 0x02 0x4f>;
				linux,phandle = <0x31>;
				phandle = <0x31>;
			};

			sdio-cmd {
				rockchip,pins = <0x00 0x03 0x02 0x50>;
				linux,phandle = <0x30>;
				phandle = <0x30>;
			};

			sdio-pwren {
				rockchip,pins = <0x00 0x1e 0x01 0x50>;
				linux,phandle = <0x2f>;
				phandle = <0x2f>;
			};

			sdio-bus4 {
				rockchip,pins = <0x01 0x01 0x02 0x50 0x01 0x02 0x02 0x50 0x01 0x04 0x02 0x50 0x01 0x05 0x02 0x50>;
				linux,phandle = <0x32>;
				phandle = <0x32>;
			};
		};

		hdmi {

			hdmii2c-xfer {
				rockchip,pins = <0x00 0x06 0x02 0x4f 0x00 0x07 0x02 0x4f>;
			};
		};

		i2s {

			i2s-bus {
				rockchip,pins = <0x00 0x08 0x01 0x4f 0x00 0x09 0x01 0x4f 0x00 0x0b 0x01 0x4f 0x00 0x0c 0x01 0x4f 0x00 0x0d 0x01 0x4f 0x00 0x0e 0x01 0x4f>;
			};

			i2s1-bus {
				rockchip,pins = <0x01 0x00 0x01 0x4f 0x01 0x01 0x01 0x4f 0x01 0x02 0x01 0x4f 0x01 0x03 0x01 0x4f 0x01 0x04 0x01 0x4f 0x01 0x05 0x01 0x4f>;
			};
		};

		pwm0 {

			pwm0-pin {
				rockchip,pins = <0x00 0x1a 0x01 0x4f>;
				linux,phandle = <0x37>;
				phandle = <0x37>;
			};
		};

		pwm1 {

			pwm1-pin {
				rockchip,pins = <0x00 0x1b 0x01 0x4f>;
				linux,phandle = <0x38>;
				phandle = <0x38>;
			};
		};

		pwm2 {

			pwm2-pin {
				rockchip,pins = <0x01 0x1c 0x01 0x4f>;
				linux,phandle = <0x39>;
				phandle = <0x39>;
			};
		};

		pwm3 {

			pwm3-pin {
				rockchip,pins = <0x03 0x1a 0x01 0x4f>;
				linux,phandle = <0x3a>;
				phandle = <0x3a>;
			};
		};

		gmac {

			rgmii-pins {
				rockchip,pins = <0x02 0x08 0x03 0x50 0x02 0x09 0x03 0x50 0x02 0x0b 0x03 0x50 0x02 0x0c 0x03 0x50 0x02 0x0d 0x03 0x50 0x02 0x0e 0x03 0x50 0x02 0x10 0x03 0x50 0x02 0x11 0x03 0x50 0x02 0x12 0x03 0x50 0x02 0x13 0x03 0x50 0x02 0x19 0x03 0x50 0x02 0x14 0x04 0x50 0x02 0x15 0x04 0x50 0x02 0x16 0x04 0x50 0x02 0x17 0x04 0x50>;
			};

			rmii-pins {
				rockchip,pins = <0x02 0x08 0x03 0x50 0x02 0x0c 0x03 0x50 0x02 0x0d 0x03 0x50 0x02 0x0e 0x03 0x50 0x02 0x0f 0x03 0x50 0x02 0x10 0x03 0x50 0x02 0x11 0x03 0x50 0x02 0x13 0x03 0x50 0x02 0x14 0x03 0x50 0x02 0x19 0x03 0x50>;
			};
		};

		spdif {

			spdif-tx {
				rockchip,pins = <0x03 0x1b 0x01 0x4f>;
				linux,phandle = <0x2a>;
				phandle = <0x2a>;
			};
		};

		spi {

			spi0-clk {
				rockchip,pins = <0x01 0x08 0x01 0x50>;
				linux,phandle = <0x4c>;
				phandle = <0x4c>;
			};

			spi0-cs0 {
				rockchip,pins = <0x01 0x0b 0x01 0x50>;
				linux,phandle = <0x4d>;
				phandle = <0x4d>;
			};

			spi0-tx {
				rockchip,pins = <0x01 0x09 0x01 0x50>;
				linux,phandle = <0x4a>;
				phandle = <0x4a>;
			};

			spi0-rx {
				rockchip,pins = <0x01 0x0a 0x01 0x50>;
				linux,phandle = <0x4b>;
				phandle = <0x4b>;
			};

			spi0-cs1 {
				rockchip,pins = <0x01 0x0c 0x01 0x50>;
				linux,phandle = <0x4e>;
				phandle = <0x4e>;
			};

			spi1-clk {
				rockchip,pins = <0x02 0x00 0x02 0x50>;
			};

			spi1-cs0 {
				rockchip,pins = <0x01 0x1e 0x03 0x50>;
			};

			spi1-tx {
				rockchip,pins = <0x01 0x1d 0x03 0x50>;
			};

			spi1-rx {
				rockchip,pins = <0x01 0x1c 0x03 0x50>;
			};

			spi1-cs1 {
				rockchip,pins = <0x01 0x1f 0x03 0x50>;
			};

			spi2-clk {
				rockchip,pins = <0x00 0x09 0x02 0x50>;
			};

			spi2-cs0 {
				rockchip,pins = <0x00 0x0e 0x02 0x50>;
			};

			spi2-tx {
				rockchip,pins = <0x00 0x0b 0x02 0x50>;
			};

			spi2-rx {
				rockchip,pins = <0x00 0x0d 0x02 0x50>;
			};
		};

		lcdc {

			lcdc-lcdc {
				rockchip,pins = <0x02 0x08 0x01 0x4f 0x02 0x0b 0x01 0x4f 0x02 0x0c 0x01 0x4f 0x02 0x0d 0x01 0x4f 0x02 0x0e 0x01 0x4f 0x02 0x0f 0x01 0x4f 0x02 0x10 0x01 0x4f 0x02 0x11 0x01 0x4f 0x02 0x12 0x01 0x4f 0x02 0x13 0x01 0x4f>;
				linux,phandle = <0x34>;
				phandle = <0x34>;
			};
		};

		pmic {

			pmic-int-l {
				rockchip,pins = <0x00 0x02 0x00 0x50>;
				linux,phandle = <0x3e>;
				phandle = <0x3e>;
			};
		};

		wireless-bluetooth {

			uart1-rts-gpio {
				rockchip,pins = <0x01 0x0b 0x00 0x4f>;
				linux,phandle = <0x5f>;
				phandle = <0x5f>;
			};
		};

		sdio-pwrseq {

			wifi-enable-h {
				rockchip,pins = <0x02 0x0d 0x00 0x4f>;
				linux,phandle = <0x56>;
				phandle = <0x56>;
			};
		};
	};

	chosen {
		bootargs = "earlycon=uart8250,mmio32,0x20068000";
	};

	cpuinfo {
		compatible = "rockchip,cpuinfo";
		nvmem-cells = <0x51>;
		nvmem-cell-names = "id";
	};

	fiq-debugger {
		compatible = "rockchip,fiq-debugger";
		rockchip,serial-id = <0x02>;
		rockchip,signal-irq = <0x9f>;
		rockchip,wake-irq = <0x00>;
		rockchip,irq-mode-enable = <0x00>;
		rockchip,baudrate = <0x1c200>;
		interrupts = <0x00 0x7f 0x08>;
		status = "okay";
	};

	reserved-memory {
		#address-cells = <0x01>;
		#size-cells = <0x01>;
		ranges;

		region@88000000 {
			compatible = "shared-dma-pool";
			reusable;
			reg = <0x88000000 0x1800000>;
			linux,phandle = <0x0d>;
			phandle = <0x0d>;
		};

		ramoops@68000000 {
			reg = <0x68000000 0xf0000>;
			linux,phandle = <0x52>;
			phandle = <0x52>;
		};

		drm-logo@00000000 {
			compatible = "rockchip,drm-logo";
			reg = <0x00 0x00>;
			linux,phandle = <0x0e>;
			phandle = <0x0e>;
		};
	};

	ramoops {
		compatible = "ramoops";
		record-size = <0x00 0x20000>;
		console-size = <0x00 0x80000>;
		ftrace-size = <0x00 0x00>;
		pmsg-size = <0x00 0x50000>;
		memory-region = <0x52>;
	};

	cif_sensor {
		compatible = "rockchip,sensor";
		status = "okay";

		hi256_b {
			is_front = <0x00>;
			powerdown-gpios = <0x2e 0x08 0x00>;
			pwdn_active = <0x01>;
			pwr_active = <0x01>;
			mir = <0x00>;
			flash_attach = <0x00>;
			resolution = <0x200000>;
			powerup_sequence = <0x7654>;
			orientation = <0x00>;
			i2c_add = <0x40>;
			i2c_chl = <0x00>;
			cif_chl = <0x00>;
			mclk_rate = <0x18>;
		};

		gc2145_b {
			is_front = <0x00>;
			powerdown-gpios = <0x2e 0x08 0x00>;
			pwdn_active = <0x01>;
			pwr_active = <0x01>;
			mir = <0x00>;
			flash_attach = <0x00>;
			resolution = <0x200000>;
			powerup_sequence = <0x7654>;
			orientation = <0x00>;
			i2c_add = <0x78>;
			i2c_chl = <0x00>;
			cif_chl = <0x00>;
			mclk_rate = <0x18>;
		};

		gc0328_b {
			is_front = <0x00>;
			powerdown-gpios = <0x2e 0x08 0x00>;
			pwdn_active = <0x01>;
			pwr_active = <0x01>;
			mir = <0x00>;
			flash_attach = <0x00>;
			resolution = <0x30000>;
			powerup_sequence = <0x7654>;
			orientation = <0x00>;
			i2c_add = <0x42>;
			i2c_chl = <0x00>;
			cif_chl = <0x00>;
			mclk_rate = <0x18>;
		};

		bf3925_b {
			is_front = <0x00>;
			powerdown-gpios = <0x2e 0x08 0x00>;
			pwdn_active = <0x01>;
			pwr_active = <0x01>;
			mir = <0x00>;
			flash_attach = <0x00>;
			resolution = <0x200000>;
			powerup_sequence = <0x7654>;
			orientation = <0x00>;
			i2c_add = <0xdc>;
			i2c_chl = <0x00>;
			cif_chl = <0x00>;
			mclk_rate = <0x18>;
		};

		sp2519_b {
			is_front = <0x00>;
			powerdown-gpios = <0x2e 0x08 0x00>;
			pwdn_active = <0x01>;
			pwr_active = <0x01>;
			mir = <0x00>;
			flash_attach = <0x00>;
			resolution = <0x200000>;
			powerup_sequence = <0x7654>;
			orientation = <0xb4>;
			i2c_add = <0x60>;
			i2c_chl = <0x00>;
			cif_chl = <0x00>;
			mclk_rate = <0x18>;
		};

		gc0312_f {
			is_front = <0x01>;
			powerdown-gpios = <0x53 0x0b 0x00>;
			pwdn_active = <0x01>;
			pwr_active = <0x01>;
			mir = <0x00>;
			flash_attach = <0x00>;
			resolution = <0x30000>;
			powerup_sequence = <0x7654>;
			orientation = <0x00>;
			i2c_add = <0x42>;
			i2c_chl = <0x00>;
			cif_chl = <0x00>;
			mclk_rate = <0x18>;
		};

		bf20a2_f {
			is_front = <0x01>;
			powerdown-gpios = <0x53 0x0b 0x00>;
			pwdn_active = <0x01>;
			pwr_active = <0x01>;
			mir = <0x00>;
			flash_attach = <0x00>;
			resolution = <0x30000>;
			powerup_sequence = <0x7654>;
			orientation = <0x00>;
			i2c_add = <0xdc>;
			i2c_chl = <0x00>;
			cif_chl = <0x00>;
			mclk_rate = <0x18>;
		};

		sp0a19_f {
			is_front = <0x01>;
			powerdown-gpios = <0x53 0x0b 0x00>;
			pwdn_active = <0x01>;
			pwr_active = <0x01>;
			mir = <0x00>;
			flash_attach = <0x00>;
			resolution = <0x30000>;
			powerup_sequence = <0x7654>;
			orientation = <0x00>;
			i2c_add = <0x42>;
			i2c_chl = <0x00>;
			cif_chl = <0x00>;
			mclk_rate = <0x18>;
		};

		sp0718_f {
			is_front = <0x01>;
			powerdown-gpios = <0x53 0x0b 0x00>;
			pwdn_active = <0x01>;
			pwr_active = <0x01>;
			mir = <0x00>;
			flash_attach = <0x00>;
			resolution = <0x30000>;
			powerup_sequence = <0x7654>;
			orientation = <0x00>;
			i2c_add = <0x42>;
			i2c_chl = <0x00>;
			cif_chl = <0x00>;
			mclk_rate = <0x18>;
		};
	};

	adc-keys {
		compatible = "adc-keys";
		io-channels = <0x54 0x02>;
		io-channel-names = "buttons";
		poll-interval = <0x64>;
		keyup-threshold-microvolt = <0x325aa0>;

		button-up {
			label = "Volume Up";
			linux,code = <0x9e>;
			press-threshold-microvolt = <0x00>;
		};

		button-down {
			label = "Volume Down";
			linux,code = <0x72>;
			press-threshold-microvolt = <0x192d50>;
		};
	};

	sdio-pwrseq {
		compatible = "mmc-pwrseq-simple";
		clocks = <0x55 0x01>;
		clock-names = "ext_clock";
		pinctrl-names = "default";
		pinctrl-0 = <0x56>;
		reset-gpios = <0x2e 0x0d 0x01>;
		linux,phandle = <0x33>;
		phandle = <0x33>;
	};

	backlight {
		compatible = "pwm-backlight";
		pwms = <0x57 0x00 0x61a8 0x00>;
		brightness-levels = <0x00 0x01 0x02 0x03 0x04 0x05 0x06 0x07 0x08 0x09 0x0a 0x0b 0x0c 0x0d 0x0e 0x0f 0x10 0x11 0x12 0x13 0x14 0x15 0x16 0x17 0x18 0x19 0x1a 0x1b 0x1c 0x1d 0x1e 0x1f 0x20 0x21 0x22 0x23 0x24 0x25 0x26 0x27 0x28 0x29 0x2a 0x2b 0x2c 0x2d 0x2e 0x2f 0x30 0x31 0x32 0x33 0x34 0x35 0x36 0x37 0x38 0x39 0x3a 0x3b 0x3c 0x3d 0x3e 0x3f 0x40 0x41 0x42 0x43 0x44 0x45 0x46 0x47 0x48 0x49 0x4a 0x4b 0x4c 0x4d 0x4e 0x4f 0x50 0x51 0x52 0x53 0x54 0x55 0x56 0x57 0x58 0x59 0x5a 0x5b 0x5c 0x5d 0x5e 0x5f 0x60 0x61 0x62 0x63 0x64 0x65 0x66 0x67 0x68 0x69 0x6a 0x6b 0x6c 0x6d 0x6e 0x6f 0x70 0x71 0x72 0x73 0x74 0x75 0x76 0x77 0x78 0x79 0x7a 0x7b 0x7c 0x7d 0x7e 0x7f 0x80 0x81 0x82 0x83 0x84 0x85 0x86 0x87 0x88 0x89 0x8a 0x8b 0x8c 0x8d 0x8e 0x8f 0x90 0x91 0x92 0x93 0x94 0x95 0x96 0x97 0x98 0x99 0x9a 0x9b 0x9c 0x9d 0x9e 0x9f 0xa0 0xa1 0xa2 0xa3 0xa4 0xa5 0xa6 0xa7 0xa8 0xa9 0xaa 0xab 0xac 0xad 0xae 0xaf 0xb0 0xb1 0xb2 0xb3 0xb4 0xb5 0xb6 0xb7 0xb8 0xb9 0xba 0xbb 0xbc 0xbd 0xbe 0xbf 0xc0 0xc1 0xc2 0xc3 0xc4 0xc5 0xc6 0xc7 0xc8 0xc9 0xca 0xcb 0xcc 0xcd 0xce 0xcf 0xd0 0xd1 0xd2 0xd3 0xd4 0xd5 0xd6 0xd7 0xd8 0xd9 0xda 0xdb 0xdc 0xdd 0xde 0xdf 0xe0 0xe1 0xe2 0xe3 0xe4 0xe5 0xe6 0xe7 0xe8 0xe9 0xea 0xeb 0xec 0xed 0xee 0xef 0xf0 0xf1 0xf2 0xf3 0xf4 0xf5 0xf6 0xf7 0xf8 0xf9 0xfa 0xfb 0xfc 0xfd 0xfe 0xff>;
		default-brightness-level = <0x80>;
		linux,phandle = <0x58>;
		phandle = <0x58>;
	};

	lvds-panel {
		status = "okay";
		compatible = "simple-panel";
		backlight = <0x58>;
		bus-format = <0x1012>;
		enable-gpios = <0x2e 0x0c 0x00>;
		prepare-delay-ms = <0x32>;
		reset-delay-ms = <0x32>;
		init-delay-ms = <0x32>;
		enable-delay-ms = <0x78>;
		disable-delay-ms = <0x14>;
		unprepare-delay-ms = <0x14>;
		rockchip,data-mapping = "jeida";
		rockchip,data-width = <0x18>;
		rockchip,output = "lvds";

		ports {

			endpoint {
				remote-endpoint = <0x59>;
				linux,phandle = <0x35>;
				phandle = <0x35>;
			};
		};

		display-timings {
			native-mode = <0x5a>;

			timing0 {
				clock-frequency = <0x30d4000>;
				hactive = <0x400>;
				vactive = <0x258>;
				hback-porch = <0xa0>;
				hfront-porch = <0xa0>;
				vback-porch = <0x17>;
				vfront-porch = <0x0c>;
				hsync-len = <0x46>;
				vsync-len = <0x0a>;
				hsync-active = <0x00>;
				vsync-active = <0x00>;
				de-active = <0x00>;
				pixelclk-active = <0x00>;
				width-mm = <0x7d>;
				height-mm = <0xdf>;
				linux,phandle = <0x5a>;
				phandle = <0x5a>;
			};
		};
	};

	firmware {

		android {
			compatible = "android,firmware";

			fstab {
				compatible = "android,fstab";

				system {
					compatible = "android,system";
					dev = "/dev/block/by-name/system";
					type = "ext4";
					mnt_flags = "ro,barrier=1,inode_readahead_blks=8";
					fsmgr_flags = "wait";
				};

				vendor {
					compatible = "android,vendor";
					dev = "/dev/block/by-name/vendor";
					type = "ext4";
					mnt_flags = "ro,barrier=1,inode_readahead_blks=8";
					fsmgr_flags = "wait";
				};
			};
		};
	};

	sound {
		compatible = "simple-audio-card";
		simple-audio-card,format = "i2s";
		simple-audio-card,mclk-fs = <0x100>;
		simple-audio-card,name = "rockchip,rk312x";

		simple-audio-card,cpu {
			sound-dai = <0x5b>;
		};

		simple-audio-card,codec {
			sound-dai = <0x5c>;
		};
	};

	uboot-charge {
		compatible = "rockchip,uboot-charge";
		rockchip,uboot-charge-on = <0x00>;
		rockchip,android-charge-on = <0x01>;
	};

	vccadc-ref {
		compatible = "regulator-fixed";
		regulator-name = "SARADC_AVDD33";
		regulator-always-on;
		regulator-boot-on;
		regulator-min-microvolt = <0x325aa0>;
		regulator-max-microvolt = <0x325aa0>;
		linux,phandle = <0x48>;
		phandle = <0x48>;
	};

	vcc-sys {
		compatible = "regulator-fixed";
		regulator-name = "vcc_sys";
		regulator-min-microvolt = "", "=\t";
		regulator-max-microvolt = "", "=\t";
		regulator-always-on;
		linux,phandle = <0x3f>;
		phandle = <0x3f>;
	};

	wireless-bluetooth {
		compatible = "bluetooth-platdata";
		uart_rts_gpios = <0x5d 0x0b 0x01>;
		pinctrl-names = "default", "rts_gpio";
		pinctrl-0 = <0x5e>;
		pinctrl-1 = <0x5f>;
		BT,reset_gpio = <0x2e 0x09 0x00>;
		BT,wake_host_irq = <0x2e 0x10 0x01>;
		status = "okay";
	};

	wireless-wlan {
		compatible = "wlan-platdata";
		wifi_chip_type = "rtl8723cs";
		WIFI,host_wake_irq = <0x3d 0x1b 0x00>;
		status = "okay";
	};
};
